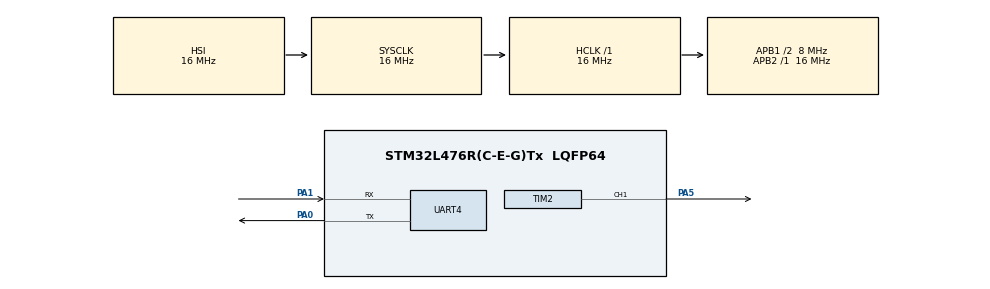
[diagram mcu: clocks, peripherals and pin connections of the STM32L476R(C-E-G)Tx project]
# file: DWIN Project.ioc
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Dma.Request0=UART4_RX
Dma.Request1=UART4_TX
Dma.UART4_RX.0.Direction=DMA_PERIPH_TO_MEMORY
Dma.UART4_RX.0.Instance=DMA2_Channel5
Dma.UART4_RX.0.MemDataAlignment=DMA_MDATAALIGN_HALFWORD
Dma.UART4_RX.0.MemInc=DMA_MINC_ENABLE
Dma.UART4_RX.0.Mode=DMA_CIRCULAR
Dma.UART4_RX.0.PeriphDataAlignment=DMA_PDATAALIGN_HALFWORD
Dma.UART4_RX.0.PeriphInc=DMA_PINC_DISABLE
Dma.UART4_RX.0.Priority=DMA_PRIORITY_MEDIUM
Dma.UART4_TX.1.Direction=DMA_MEMORY_TO_PERIPH
Dma.UART4_TX.1.Instance=DMA2_Channel3
Dma.UART4_TX.1.MemDataAlignment=DMA_MDATAALIGN_BYTE
Dma.UART4_TX.1.MemInc=DMA_MINC_ENABLE
Dma.UART4_TX.1.Mode=DMA_NORMAL
Dma.UART4_TX.1.PeriphDataAlignment=DMA_PDATAALIGN_BYTE
Dma.UART4_TX.1.PeriphInc=DMA_PINC_DISABLE
Dma.UART4_TX.1.Priority=DMA_PRIORITY_MEDIUM
Mcu.Family=STM32L4
Mcu.Name=STM32L476R(C-E-G)Tx
Mcu.Package=LQFP64
NVIC.DMA2_Channel3_IRQn=true\:0\:0\:false\:false\:true\:false\:true
NVIC.DMA2_Channel5_IRQn=true\:0\:0\:false\:false\:true\:false\:true
NVIC.PriorityGroup=NVIC_PRIORITYGROUP_4
NVIC.TIM2_IRQn=true\:0\:0\:false\:false\:true\:true\:true
NVIC.UART4_IRQn=true\:0\:0\:false\:false\:true\:true\:true
PA0.Mode=Asynchronous
PA0.Signal=UART4_TX
PA1.Mode=Asynchronous
PA1.Signal=UART4_RX
PA13\ (JTMS-SWDIO).Mode=Serial_Wire
PA13\ (JTMS-SWDIO).Signal=SYS_JTMS-SWDIO
PA14\ (JTCK-SWCLK).Mode=Serial_Wire
PA14\ (JTCK-SWCLK).Signal=SYS_JTCK-SWCLK
PA5.Signal=S_TIM2_CH1
PC14-OSC32_IN\ (PC14).Mode=LSE-External-Oscillator
PC14-OSC32_IN\ (PC14).Signal=RCC_OSC32_IN
PC15-OSC32_OUT\ (PC15).Mode=LSE-External-Oscillator
PC15-OSC32_OUT\ (PC15).Signal=RCC_OSC32_OUT
ProjectManager.HeapSize=0x200
ProjectManager.StackSize=0x400
ProjectManager.TargetToolchain=STM32CubeIDE
RCC.ADCPresc=RCC_ADCPCLK2_DIV4
RCC.AHBFreq_Value=16000000
RCC.APB1CLKDivider=RCC_HCLK_DIV2
RCC.APB1Freq_Value=8000000
RCC.APB1TimFreq_Value=16000000
RCC.APB2Freq_Value=16000000
RCC.APB2TimFreq_Value=16000000
RCC.CortexFreq_Value=16000000
RCC.HCLKFreq_Value=16000000
RCC.HSE_VALUE=8000000
RCC.HSI_VALUE=16000000
RCC.MSI_VALUE=4000000
RCC.PLLMUL=RCC_PLL_MUL6
RCC.RTCClockSelection=RCC_RTCCLKSOURCE_LSE
RCC.SYSCLKFreq_VALUE=16000000
RCC.SYSCLKSource=RCC_SYSCLKSOURCE_HSI
RCC.USBFreq_Value=16000000
RCC.VCOOutputFreq_Value=32000000
RTC.Format=RTC_FORMAT_BIN
RTC.Hours=12
RTC.Minutes=30
RTC.Seconds=47
SH.S_TIM2_CH1.0=TIM2_CH1,PWM Generation1 CH1
TIM2.Channel-PWM\ Generation1\ CH1=TIM_CHANNEL_1
TIM2.Period=65535
TIM2.Prescaler=0
VP_RTC_VS_RTC_Activate.Mode=RTC_Enabled
VP_RTC_VS_RTC_Calendar.Mode=RTC_Calendar
VP_TIM2_VS_ClockSourceINT.Mode=Internal
board=custom

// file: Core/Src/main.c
/* USER CODE BEGIN Header */
/**
  ******************************************************************************
  * @file           : main.c
  * @brief          : Main program body
  ******************************************************************************
  * @attention
  *
  * <h2><center>&copy; Copyright (c) 2021 STMicroelectronics.
  * All rights reserved.</center></h2>
  *
  * This software component is licensed by ST under BSD 3-Clause license,
  * the "License"; You may not use this file except in compliance with the
  * License. You may obtain a copy of the License at:
  *                        opensource.org/licenses/BSD-3-Clause
  *
  ******************************************************************************
  */
/* USER CODE END Header */
#include "main.h"
#include "dma.h"
#include "rtc.h"
#include "tim.h"
#include "usart.h"
#include "gpio.h"

/* USER CODE BEGIN Includes */
#include "DWIN.h"
#include "DWIN_APP.h"
/* USER CODE END Includes */

void SystemClock_Config(void);

int main(void)
{

  /* MCU Configuration--------------------------------------------------------*/

  /* Reset of all peripherals, Initializes the Flash interface and the Systick. */
  HAL_Init();

  /* Configure the system clock */
  SystemClock_Config();

  /* Initialize all configured peripherals */
  MX_GPIO_Init();
  MX_DMA_Init();
  MX_RTC_Init();
  MX_TIM2_Init();
  MX_UART4_Init();
  /* USER CODE BEGIN 2 */
  dwinUartDmaInit();
  dwinAppInit();
  uint16_t i =0;
  /* USER CODE END 2 */

  /* Infinite loop */
  /* USER CODE BEGIN WHILE */
  while (1)
  {
	  parsingDWIN();
	  if ( i < 100)
	  {
		  i++;
		  writeHalfWordDWIN(0x5002, i);
		  parsingDWIN();
		  HAL_Delay(50);
		  writeHalfWordDWIN(0x5004, 100-i);
		  parsingDWIN();
	  HAL_Delay(50);
	  }
	  else
	  {
		  i = 0;
	  }
	  ledPWM();

    /* USER CODE END WHILE */

  }
}

void SystemClock_Config(void)
{
  RCC_OscInitTypeDef RCC_OscInitStruct = {0};
  RCC_ClkInitTypeDef RCC_ClkInitStruct = {0};

  /** Configure the main internal regulator output voltage
  */
  if (HAL_PWREx_ControlVoltageScaling(PWR_REGULATOR_VOLTAGE_SCALE1) != HAL_OK)
  {
    Error_Handler();
  }
  /** Configure LSE Drive Capability
  */
  HAL_PWR_EnableBkUpAccess();
  __HAL_RCC_LSEDRIVE_CONFIG(RCC_LSEDRIVE_LOW);
  /** Initializes the RCC Oscillators according to the specified parameters
  * in the RCC_OscInitTypeDef structure.
  */
  RCC_OscInitStruct.OscillatorType = RCC_OSCILLATORTYPE_HSI|RCC_OSCILLATORTYPE_LSE;
  RCC_OscInitStruct.LSEState = RCC_LSE_ON;
  RCC_OscInitStruct.HSIState = RCC_HSI_ON;
  RCC_OscInitStruct.HSICalibrationValue = RCC_HSICALIBRATION_DEFAULT;
  RCC_OscInitStruct.PLL.PLLState = RCC_PLL_NONE;
  if (HAL_RCC_OscConfig(&RCC_OscInitStruct) != HAL_OK)
  {
    Error_Handler();
  }
  /** Initializes the CPU, AHB and APB buses clocks
  */
  RCC_ClkInitStruct.ClockType = RCC_CLOCKTYPE_HCLK|RCC_CLOCKTYPE_SYSCLK
                              |RCC_CLOCKTYPE_PCLK1|RCC_CLOCKTYPE_PCLK2;
  RCC_ClkInitStruct.SYSCLKSource = RCC_SYSCLKSOURCE_HSI;
  RCC_ClkInitStruct.AHBCLKDivider = RCC_SYSCLK_DIV1;
  RCC_ClkInitStruct.APB1CLKDivider = RCC_HCLK_DIV2;
  RCC_ClkInitStruct.APB2CLKDivider = RCC_HCLK_DIV1;

  if (HAL_RCC_ClockConfig(&RCC_ClkInitStruct, FLASH_LATENCY_0) != HAL_OK)
  {
    Error_Handler();
  }
}

void Error_Handler(void)
{
  __disable_irq();
  while (1)
  {
  }
}
